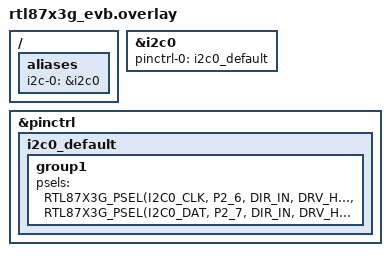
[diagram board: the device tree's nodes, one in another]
&i2c0 {
    pinctrl-0 = <&i2c0_default>;
    pinctrl-names = "default";
    status = "okay";
};

/ {
    aliases {
        i2c-0 = &i2c0;
    };
};

&pinctrl {
    i2c0_default: i2c0_default {
        group1 {
            psels = <RTL87X3G_PSEL(I2C0_CLK, P2_6, DIR_IN, DRV_HIGH, PULL_UP)>,
             <RTL87X3G_PSEL(I2C0_DAT, P2_7, DIR_IN, DRV_HIGH, PULL_UP)>;
        };
    };
};
